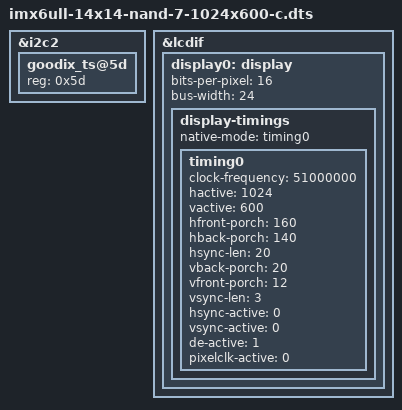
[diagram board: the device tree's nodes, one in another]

#include "imx6ull-14x14-evk-gpmi-weim.dts"

&i2c2 {
	goodix_ts@5d {
		reg = <0x5d>;
	};
};

&lcdif {
	display0: display {
		bits-per-pixel = <16>;
		bus-width = <24>;

		display-timings {
			native-mode = <&timing0>;
			timing0: timing0 {
			clock-frequency = <51000000>;
			hactive = <1024>;
			vactive = <600>;
			hfront-porch = <160>;
			hback-porch = <140>;
			hsync-len = <20>;
			vback-porch = <20>;
			vfront-porch = <12>;
			vsync-len = <3>;

			hsync-active = <0>;
			vsync-active = <0>;
			de-active = <1>;
			pixelclk-active = <0>;
			};
		};
	};
};
